# STM32MP157x register map
File version: 1.3
Registers are 32-bit, read-write, reset 0x0 unless marked. A register's access mark holds for its fields unless they carry their own. Offsets are from the block's base; [hi:lo] are bit positions; {n}, {i} and the like mark numbered series; 'fields as' and 'values as' point back to an identical list.

## SYSCFG
Base 0x50020000
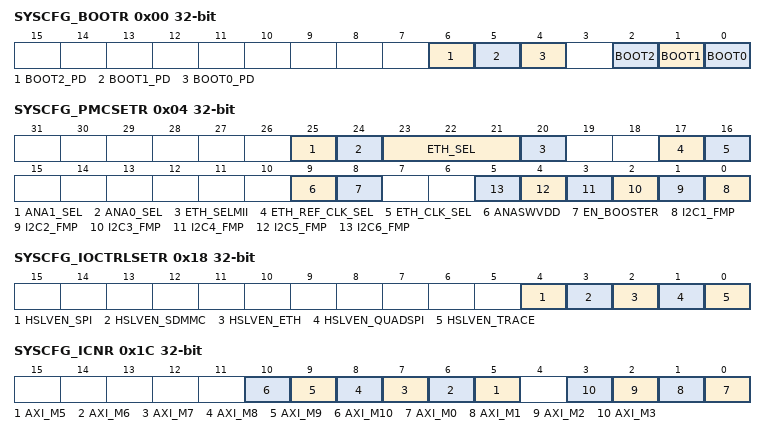
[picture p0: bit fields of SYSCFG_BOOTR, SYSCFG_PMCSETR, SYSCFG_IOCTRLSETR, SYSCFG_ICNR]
0x00 SYSCFG_BOOTR access per field — This register is used to know the state of BOOT pins and to control pull-up to reduce the static power consumption on the pin set to high level. )
  [6] BOOT2_PD rw, [5] BOOT1_PD rw, [4] BOOT0_PD rw, [2] BOOT2 ro, [1] BOOT1 ro, [0] BOOT0 ro
0x04 SYSCFG_PMCSETR — SYSCFG peripheral mode configuration set register
  [25] ANA1_SEL, [24] ANA0_SEL, [23:21] ETH_SEL, [20] ETH_SELMII, [17] ETH_REF_CLK_SEL, [16] ETH_CLK_SEL, [9] ANASWVDD, [8] EN_BOOSTER, [n-1] I2C{n}_FMP (n=1..6)
0x18 SYSCFG_IOCTRLSETR — SYSCFG IO control register
  [4] HSLVEN_SPI, [3] HSLVEN_SDMMC, [2] HSLVEN_ETH, [1] HSLVEN_QUADSPI, [0] HSLVEN_TRACE
0x1C SYSCFG_ICNR — SYSCFG interconnect control register
  [n] AXI_M{n} (n=5..10), [n] AXI_M{n} (n=0..3)
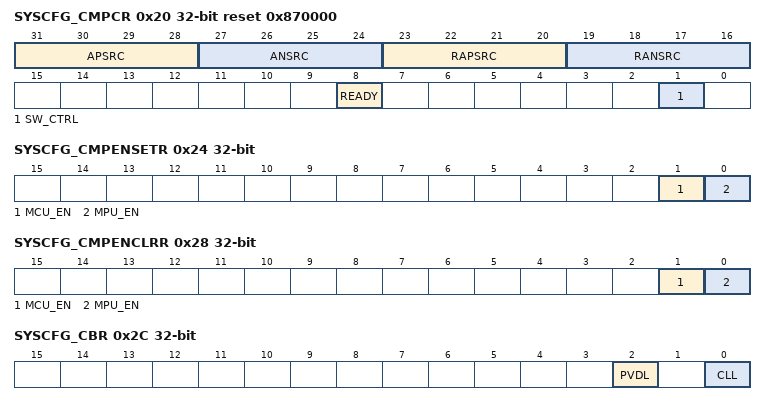
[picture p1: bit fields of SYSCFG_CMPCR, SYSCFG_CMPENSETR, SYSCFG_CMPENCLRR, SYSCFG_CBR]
0x20 SYSCFG_CMPCR access per field reset 0x870000 — SYSCFG compensation cell control register
  [31:28] APSRC ro, [27:24] ANSRC ro, [23:20] RAPSRC rw, [19:16] RANSRC rw, [8] READY ro, [1] SW_CTRL rw
0x24 SYSCFG_CMPENSETR — SYSCFG compensation cell enable set register
  [1] MCU_EN, [0] MPU_EN
0x28 SYSCFG_CMPENCLRR — SYSCFG compensation cell enable set register
  [1] MCU_EN, [0] MPU_EN
0x2C SYSCFG_CBR — SYSCFG control timer break register
  [2] PVDL, [0] CLL
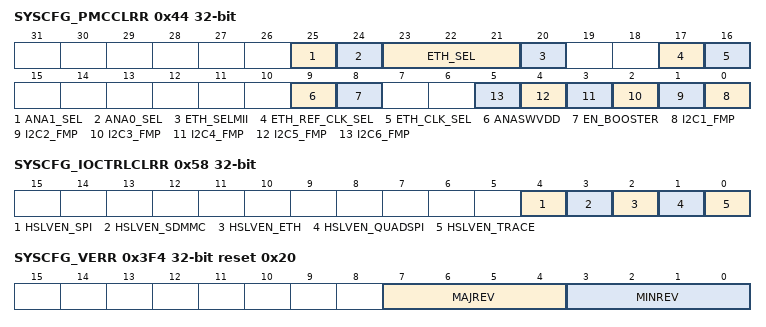
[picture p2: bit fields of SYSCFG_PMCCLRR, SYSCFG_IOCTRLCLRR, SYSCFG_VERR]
0x44 SYSCFG_PMCCLRR — SYSCFG peripheral mode configuration clear register
  fields as SYSCFG_PMCSETR
0x58 SYSCFG_IOCTRLCLRR — SYSCFG IO control register
  fields as SYSCFG_IOCTRLSETR
0x3F4 SYSCFG_VERR ro reset 0x20 — SYSCFG version register
  [7:4] MAJREV, [3:0] MINREV
0x3F8 SYSCFG_IPIDR ro reset 0x30001 — SYSCFG identification register
  [31:0] ID
0x3FC SYSCFG_SIDR ro reset 0xA3C5DD01 — SYSCFG size identification register
  [31:0] SID

## IPCC
Base 0x4C001000
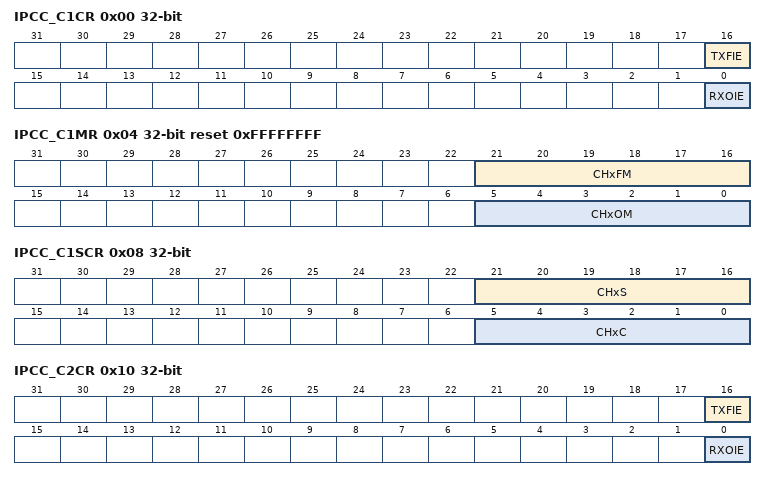
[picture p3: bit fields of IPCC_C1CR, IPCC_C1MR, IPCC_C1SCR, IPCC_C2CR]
0x00 IPCC_C1CR — IPCC Processor 1 control register
  [16] TXFIE, [0] RXOIE
0x04 IPCC_C1MR reset 0xFFFFFFFF — IPCC Processor 1 mask register
  [21:16] CHxFM, [5:0] CHxOM
0x08 IPCC_C1SCR — Reading this register will always return 0x0000 0000.
  [21:16] CHxS, [5:0] CHxC
0x0C IPCC_C1TOC2SR ro — IPCC processor 1 to processor 2 status register
  [5:0] CHxF
0x10 IPCC_C2CR — IPCC Processor 2 control register
  [16] TXFIE, [0] RXOIE
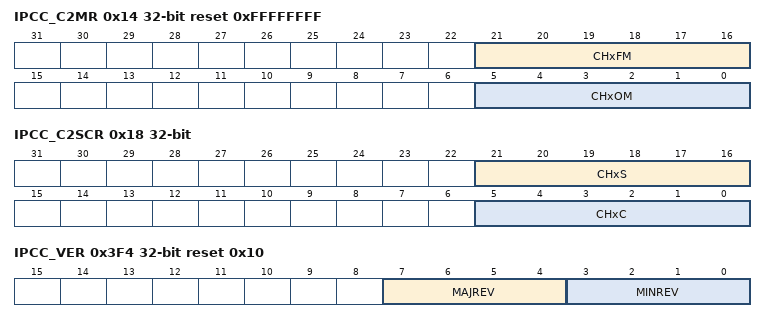
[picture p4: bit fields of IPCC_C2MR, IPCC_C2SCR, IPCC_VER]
0x14 IPCC_C2MR reset 0xFFFFFFFF — IPCC Processor 2 mask register
  [21:16] CHxFM, [5:0] CHxOM
0x18 IPCC_C2SCR — Reading this register will always return 0x0000 0000.
  [21:16] CHxS, [5:0] CHxC
0x1C IPCC_C2TOC1SR ro — IPCC processor 2 to processor 1 status register
  [5:0] CHxF
0x3F0 IPCC_HWCFGR ro reset 0x2 — IPCC Hardware configuration register
  [7:0] CHANNELS
0x3F4 IPCC_VER ro reset 0x10 — IPCC IP Version register
  [7:4] MAJREV, [3:0] MINREV
0x3F8 IPCC_ID ro reset 0x100071 — IPCC IP Identification register
  [31:0] IPID
0x3FC IPCC_SID ro reset 0xA3C5DD01 — IPCC Size ID register

## MDIOS
Base 0x4001C000
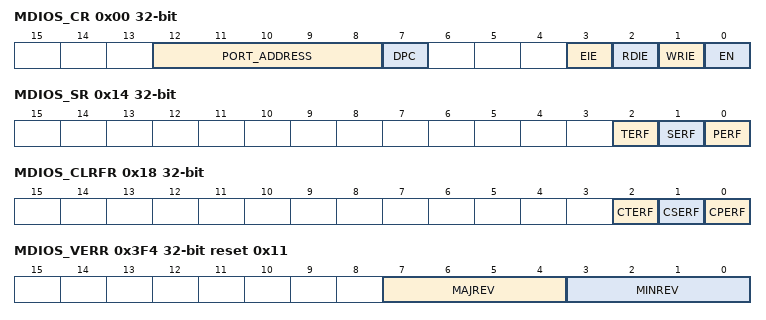
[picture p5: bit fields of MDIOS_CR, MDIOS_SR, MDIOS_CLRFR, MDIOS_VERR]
0x00 MDIOS_CR — MDIOS configuration register
  [12:8] PORT_ADDRESS, [7] DPC, [3] EIE, [2] RDIE, [1] WRIE, [0] EN
0x04 MDIOS_WRFR ro — MDIOS write flag register
  [31:0] WRF
0x08 MDIOS_CWRFR — MDIOS clear write flag register
  [31:0] CWRF
0x0C MDIOS_RDFR ro — MDIOS read flag register
  [31:0] RDF
0x10 MDIOS_CRDFR — MDIOS clear read flag register
  [31:0] CRDF
0x14 MDIOS_SR ro — MDIOS status register
  [2] TERF, [1] SERF, [0] PERF
0x18 MDIOS_CLRFR — MDIOS clear flag register
  [2] CTERF, [1] CSERF, [0] CPERF
{0x100+4i} MDIOS_DINR{i} ro (i=0..31) — MDIOS input data register
  [15:0] DIN
0x180 MDIOS_DOUTR0 ro — MDIOS input data register
  [15:0] DOUT
0x184 MDIOS_DOUTR1 ro — MDIOS input data register
  [15:0] DOUT
{0x180+4i} MDIOS_DOUTR{i} ro (i=2..31) — MDIOS output data register
  [15:0] DOUT
0x3F0 MDIOS_HWCFGR ro reset 0x20 — MDIOS HW configuration register
  [7:0] NBREG
0x3F4 MDIOS_VERR ro reset 0x11 — MDIOS version register
  [7:4] MAJREV, [3:0] MINREV
0x3F8 MDIOS_IPIDR ro reset 0x180001 — MDIOS identification register
  [31:0] ID
0x3FC MDIOS_SIDR ro reset 0xA3C5DD01 — MDIOS size identification register
  [31:0] SID
